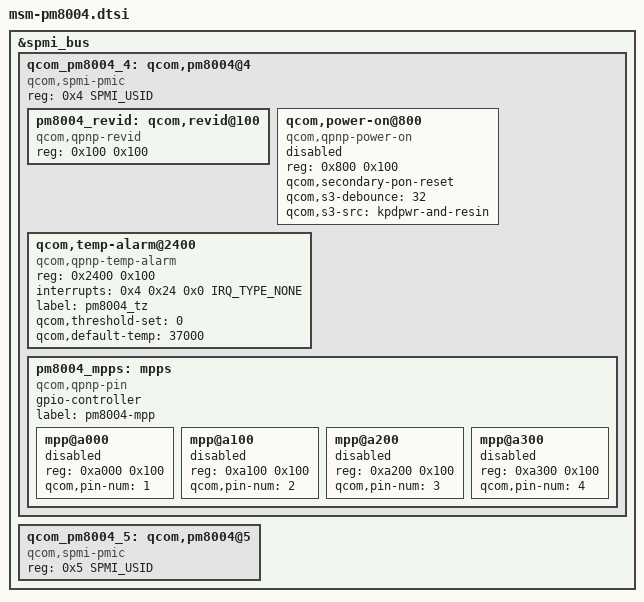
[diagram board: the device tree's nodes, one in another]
/* Copyright (c) 2014-2015, 2019, The Linux Foundation. All rights reserved.
 *
 * This program is free software; you can redistribute it and/or modify
 * it under the terms of the GNU General Public License version 2 and
 * only version 2 as published by the Free Software Foundation.
 *
 * This program is distributed in the hope that it will be useful,
 * but WITHOUT ANY WARRANTY; without even the implied warranty of
 * MERCHANTABILITY or FITNESS FOR A PARTICULAR PURPOSE.  See the
 * GNU General Public License for more details.
 */

#include <dt-bindings/spmi/spmi.h>
#include <dt-bindings/interrupt-controller/irq.h>

&spmi_bus {
	qcom_pm8004_4: qcom,pm8004@4 {
		compatible = "qcom,spmi-pmic";
		reg = <0x4 SPMI_USID>;
		#address-cells = <2>;
		#size-cells = <0>;

		pm8004_revid: qcom,revid@100 {
			compatible = "qcom,qpnp-revid";
			reg = <0x100 0x100>;
		};

		qcom,power-on@800 {
			compatible = "qcom,qpnp-power-on";
			reg = <0x800 0x100>;
			qcom,secondary-pon-reset;
			qcom,s3-debounce = <32>;
			qcom,s3-src = "kpdpwr-and-resin";
			status = "disabled";
		};

		qcom,temp-alarm@2400 {
			compatible = "qcom,qpnp-temp-alarm";
			reg = <0x2400 0x100>;
			interrupts = <0x4 0x24 0x0 IRQ_TYPE_NONE>;
			label = "pm8004_tz";
			qcom,threshold-set = <0>;
			qcom,default-temp = <37000>;
		};

		pm8004_mpps: mpps {
			compatible = "qcom,qpnp-pin";
			gpio-controller;
			#gpio-cells = <2>;
			#address-cells = <1>;
			#size-cells = <1>;
			label = "pm8004-mpp";

			mpp@a000 {
				reg = <0xa000 0x100>;
				qcom,pin-num = <1>;
				status = "disabled";
			};

			mpp@a100 {
				reg = <0xa100 0x100>;
				qcom,pin-num = <2>;
				status = "disabled";
			};

			mpp@a200 {
				reg = <0xa200 0x100>;
				qcom,pin-num = <3>;
				status = "disabled";
			};

			mpp@a300 {
				reg = <0xa300 0x100>;
				qcom,pin-num = <4>;
				status = "disabled";
			};
		};
	};

	qcom_pm8004_5: qcom,pm8004@5 {
		compatible ="qcom,spmi-pmic";
		reg = <0x5 SPMI_USID>;
		#address-cells = <2>;
		#size-cells = <0>;
	};
};
